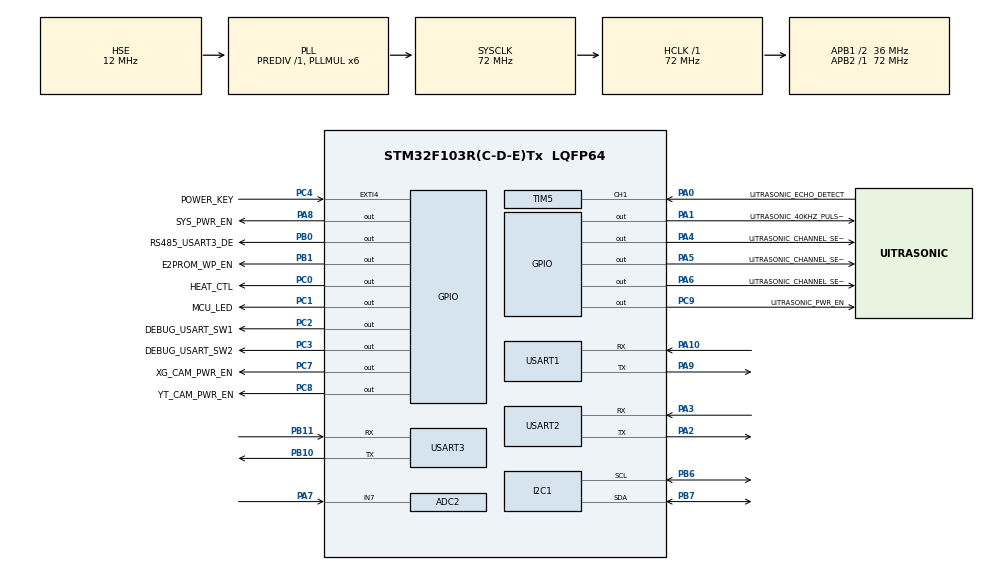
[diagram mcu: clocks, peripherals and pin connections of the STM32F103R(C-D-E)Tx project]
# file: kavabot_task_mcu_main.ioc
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ADC2.Channel-0\#ChannelRegularConversion=ADC_CHANNEL_7
ADC2.NbrOfConversionFlag=1
ADC2.Rank-0\#ChannelRegularConversion=1
ADC2.SamplingTime-0\#ChannelRegularConversion=ADC_SAMPLETIME_1CYCLE_5
Dma.Request0=USART3_RX
Dma.USART3_RX.0.Direction=DMA_PERIPH_TO_MEMORY
Dma.USART3_RX.0.Instance=DMA1_Channel3
Dma.USART3_RX.0.MemDataAlignment=DMA_MDATAALIGN_BYTE
Dma.USART3_RX.0.MemInc=DMA_MINC_ENABLE
Dma.USART3_RX.0.Mode=DMA_NORMAL
Dma.USART3_RX.0.PeriphDataAlignment=DMA_PDATAALIGN_BYTE
Dma.USART3_RX.0.PeriphInc=DMA_PINC_DISABLE
Dma.USART3_RX.0.Priority=DMA_PRIORITY_LOW
Mcu.Family=STM32F1
Mcu.Name=STM32F103R(C-D-E)Tx
Mcu.Package=LQFP64
NVIC.DMA1_Channel3_IRQn=true\:5\:0\:true\:false\:true\:false\:true
NVIC.EXTI4_IRQn=true\:5\:0\:true\:false\:true\:true\:true
NVIC.PriorityGroup=NVIC_PRIORITYGROUP_4
NVIC.TIM1_UP_IRQn=true\:5\:0\:true\:false\:true\:true\:true
NVIC.TIM3_IRQn=true\:5\:0\:true\:false\:true\:true\:true
NVIC.TIM4_IRQn=true\:2\:0\:true\:false\:true\:true\:true
NVIC.TIM5_IRQn=true\:1\:0\:true\:false\:true\:true\:true
NVIC.USART1_IRQn=true\:5\:0\:true\:false\:true\:true\:true
NVIC.USART2_IRQn=true\:3\:0\:true\:false\:true\:true\:true
NVIC.USART3_IRQn=true\:5\:0\:true\:false\:true\:true\:true
PA0-WKUP.GPIO_Label=UITRASONIC_ECHO_DETECT
PA0-WKUP.Signal=S_TIM5_CH1
PA1.GPIO_Label=UITRASONIC_40KHZ_PULSE_OUTPUT
PA1.Signal=GPIO_Output
PA10.Mode=Asynchronous
PA10.Signal=USART1_RX
PA13.Mode=Serial_Wire
PA13.Signal=SYS_JTMS-SWDIO
PA14.Mode=Serial_Wire
PA14.Signal=SYS_JTCK-SWCLK
PA2.Mode=Asynchronous
PA2.Signal=USART2_TX
PA3.Mode=Asynchronous
PA3.Signal=USART2_RX
PA4.GPIO_Label=UITRASONIC_CHANNEL_SEL_0
PA4.Signal=GPIO_Output
PA5.GPIO_Label=UITRASONIC_CHANNEL_SEL_1
PA5.Signal=GPIO_Output
PA6.GPIO_Label=UITRASONIC_CHANNEL_SEL_2
PA6.Signal=GPIO_Output
PA7.Signal=ADCx_IN7
PA8.GPIO_Label=SYS_PWR_EN
PA8.Signal=GPIO_Output
PA9.Mode=Asynchronous
PA9.Signal=USART1_TX
PB0.GPIO_Label=RS485_USART3_DE
PB0.Signal=GPIO_Output
PB1.GPIO_Label=E2PROM_WP_EN
PB1.Signal=GPIO_Output
PB10.Mode=Asynchronous
PB10.Signal=USART3_TX
PB11.Mode=Asynchronous
PB11.Signal=USART3_RX
PB6.Mode=I2C
PB6.Signal=I2C1_SCL
PB7.Mode=I2C
PB7.Signal=I2C1_SDA
PC0.GPIO_Label=HEAT_CTL
PC0.Signal=GPIO_Output
PC1.GPIO_Label=MCU_LED
PC1.Signal=GPIO_Output
PC14-OSC32_IN.Mode=LSE-External-Oscillator
PC14-OSC32_IN.Signal=RCC_OSC32_IN
PC15-OSC32_OUT.Mode=LSE-External-Oscillator
PC15-OSC32_OUT.Signal=RCC_OSC32_OUT
PC2.GPIO_Label=DEBUG_USART_SW1
PC2.Signal=GPIO_Output
PC3.GPIO_Label=DEBUG_USART_SW2
PC3.Signal=GPIO_Output
PC4.GPIO_Label=POWER_KEY
PC4.Signal=GPXTI4
PC7.GPIO_Label=XG_CAM_PWR_EN
PC7.Signal=GPIO_Output
PC8.GPIO_Label=YT_CAM_PWR_EN
PC8.Signal=GPIO_Output
PC9.GPIO_Label=UITRASONIC_PWR_EN
PC9.Signal=GPIO_Output
PD0-OSC_IN.Mode=HSE-External-Oscillator
PD0-OSC_IN.Signal=RCC_OSC_IN
PD1-OSC_OUT.Mode=HSE-External-Oscillator
PD1-OSC_OUT.Signal=RCC_OSC_OUT
ProjectManager.HeapSize=0x200
ProjectManager.StackSize=0x200
ProjectManager.TargetToolchain=Makefile
RCC.ADCPresc=RCC_ADCPCLK2_DIV6
RCC.AHBFreq_Value=72000000
RCC.APB1CLKDivider=RCC_HCLK_DIV2
RCC.APB1Freq_Value=36000000
RCC.APB1TimFreq_Value=72000000
RCC.APB2Freq_Value=72000000
RCC.APB2TimFreq_Value=72000000
RCC.HCLKFreq_Value=72000000
RCC.HSE_VALUE=12000000
RCC.PLLMUL=RCC_PLL_MUL6
RCC.PLLSourceVirtual=RCC_PLLSOURCE_HSE
RCC.SYSCLKFreq_VALUE=72000000
RCC.SYSCLKSource=RCC_SYSCLKSOURCE_PLLCLK
RCC.USBFreq_Value=72000000
RTC.Hours=12
RTC.Minutes=12
RTC.Month=RTC_MONTH_MAY
RTC.Seconds=12
RTC.WeekDay=RTC_WEEKDAY_TUESDAY
RTC.Year=21
SH.ADCx_IN7.0=ADC2_IN7,IN7
SH.S_TIM5_CH1.0=TIM5_CH1,Input_Capture1_from_TI1
TIM1.AutoReloadPreload=TIM_AUTORELOAD_PRELOAD_ENABLE
TIM1.Period=5000 - 1
TIM1.Prescaler=72 - 1
TIM3.AutoReloadPreload=TIM_AUTORELOAD_PRELOAD_ENABLE
TIM3.Period=35 - 1
TIM3.Prescaler=3600 - 1
TIM4.AutoReloadPreload=TIM_AUTORELOAD_PRELOAD_ENABLE
TIM4.Period=50 - 1
TIM4.Prescaler=72 - 1
TIM5.AutoReloadPreload=TIM_AUTORELOAD_PRELOAD_ENABLE
TIM5.Channel-Input_Capture1_from_TI1=TIM_CHANNEL_1
TIM5.ICPolarity_CH1=TIM_INPUTCHANNELPOLARITY_FALLING
TIM5.Period=20000 - 1
TIM5.Prescaler=72 - 1
TIM6.AutoReloadPreload=TIM_AUTORELOAD_PRELOAD_ENABLE
TIM6.Period=65536 - 1
TIM6.Prescaler=72 - 1
USART1.VirtualMode=VM_ASYNC
USART2.VirtualMode=VM_ASYNC
USART3.VirtualMode=VM_ASYNC
VP_RTC_VS_RTC_Activate.Mode=RTC_Enabled
VP_RTC_VS_RTC_Calendar.Mode=RTC_Calendar
VP_TIM1_VS_ClockSourceINT.Mode=Internal
VP_TIM3_VS_ClockSourceINT.Mode=Internal
VP_TIM4_VS_ClockSourceINT.Mode=Internal
VP_TIM5_VS_ClockSourceINT.Mode=Internal
VP_TIM6_VS_ClockSourceINT.Mode=Enable_Timer
board=custom

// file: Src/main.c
/* USER CODE BEGIN Header */
/**
 ******************************************************************************
 * @file           : main.c
 * @brief          : Main program body
 ******************************************************************************
 * @attention
 *
 * <h2><center>&copy; Copyright (c) 2021 STMicroelectronics.
 * All rights reserved.</center></h2>
 *
 * This software component is licensed by ST under BSD 3-Clause license,
 * the "License"; You may not use this file except in compliance with the
 * License. You may obtain a copy of the License at:
 *                        opensource.org/licenses/BSD-3-Clause
 *
 ******************************************************************************
 */
/* USER CODE END Header */
#include "main.h"
#include "adc.h"
#include "dma.h"
#include "i2c.h"
#include "rtc.h"
#include "tim.h"
#include "usart.h"
#include "gpio.h"

/* USER CODE BEGIN Includes */
#include "app.h"
#include "fal_uitrasonic.h"
/* USER CODE END Includes */

void SystemClock_Config(void);

int main(void) {

    /* MCU
     * Configuration--------------------------------------------------------*/

    /* Reset of all peripherals, Initializes the Flash interface and the
     * Systick. */
    HAL_Init();

    /* Configure the system clock */
    SystemClock_Config();

    /* Initialize all configured peripherals */
    MX_GPIO_Init();
    MX_DMA_Init();
    MX_ADC2_Init();
    MX_I2C1_Init();
    MX_RTC_Init();
    MX_TIM1_Init();
    MX_TIM3_Init();
    MX_TIM6_Init();
    MX_USART1_UART_Init();
    MX_USART2_UART_Init();
    MX_USART3_UART_Init();
    MX_TIM4_Init();
    MX_TIM5_Init();
    /* USER CODE BEGIN 2 */
    app_init();
    /* USER CODE END 2 */

    /* Infinite loop */
    while (1) {

        /* USER CODE BEGIN 3 */
        fal_uitrasonic_server();
    }
    /* USER CODE END 3 */
}

void SystemClock_Config(void) {
    RCC_OscInitTypeDef RCC_OscInitStruct = {0};
    RCC_ClkInitTypeDef RCC_ClkInitStruct = {0};
    RCC_PeriphCLKInitTypeDef PeriphClkInit = {0};

    /** Initializes the RCC Oscillators according to the specified parameters
     * in the RCC_OscInitTypeDef structure.
     */
    RCC_OscInitStruct.OscillatorType =
        RCC_OSCILLATORTYPE_LSI | RCC_OSCILLATORTYPE_HSE;
    RCC_OscInitStruct.HSEState = RCC_HSE_ON;
    RCC_OscInitStruct.HSEPredivValue = RCC_HSE_PREDIV_DIV1;
    RCC_OscInitStruct.HSIState = RCC_HSI_ON;
    RCC_OscInitStruct.LSIState = RCC_LSI_ON;
    RCC_OscInitStruct.PLL.PLLState = RCC_PLL_ON;
    RCC_OscInitStruct.PLL.PLLSource = RCC_PLLSOURCE_HSE;
    RCC_OscInitStruct.PLL.PLLMUL = RCC_PLL_MUL6;
    if (HAL_RCC_OscConfig(&RCC_OscInitStruct) != HAL_OK) {
        Error_Handler();
    }
    /** Initializes the CPU, AHB and APB buses clocks
     */
    RCC_ClkInitStruct.ClockType = RCC_CLOCKTYPE_HCLK | RCC_CLOCKTYPE_SYSCLK |
                                  RCC_CLOCKTYPE_PCLK1 | RCC_CLOCKTYPE_PCLK2;
    RCC_ClkInitStruct.SYSCLKSource = RCC_SYSCLKSOURCE_PLLCLK;
    RCC_ClkInitStruct.AHBCLKDivider = RCC_SYSCLK_DIV1;
    RCC_ClkInitStruct.APB1CLKDivider = RCC_HCLK_DIV2;
    RCC_ClkInitStruct.APB2CLKDivider = RCC_HCLK_DIV1;

    if (HAL_RCC_ClockConfig(&RCC_ClkInitStruct, FLASH_LATENCY_2) != HAL_OK) {
        Error_Handler();
    }
    PeriphClkInit.PeriphClockSelection = RCC_PERIPHCLK_RTC | RCC_PERIPHCLK_ADC;
    PeriphClkInit.RTCClockSelection = RCC_RTCCLKSOURCE_LSI;
    PeriphClkInit.AdcClockSelection = RCC_ADCPCLK2_DIV6;
    if (HAL_RCCEx_PeriphCLKConfig(&PeriphClkInit) != HAL_OK) {
        Error_Handler();
    }
}

void Error_Handler(void) {
    /* USER CODE BEGIN Error_Handler_Debug */
    /* User can add his own implementation to report the HAL error return state
     */
    __disable_irq();
    while (1) {}
    /* USER CODE END Error_Handler_Debug */
}

#ifdef USE_FULL_ASSERT
/**
 * @brief  Reports the name of the source file and the source line number
 *         where the assert_param error has occurred.
 * @param  file: pointer to the source file name
 * @param  line: assert_param error line source number
 * @retval None
 */
void assert_failed(uint8_t *file, uint32_t line) {
    /* USER CODE BEGIN 6 */
    /* User can add his own implementation to report the file name and line
       number, ex: printf("Wrong parameters value: file %s on line %d\r\n",
       file, line) */
    /* USER CODE END 6 */
}
#endif /* USE_FULL_ASSERT */

/************************ (C) COPYRIGHT STMicroelectronics *****END OF FILE****/
